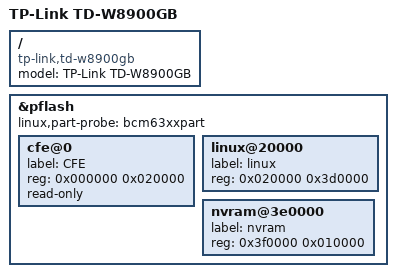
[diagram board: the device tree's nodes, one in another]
/dts-v1/;

/include/ "bcm6348.dtsi"

/ {
	model = "TP-Link TD-W8900GB";
	compatible = "tp-link,td-w8900gb", "brcm,bcm6348";
};

&pflash {
	status = "ok";

	linux,part-probe = "bcm63xxpart";

	cfe@0 {
		label = "CFE";
		reg = <0x000000 0x020000>;
		read-only;
	};

	linux@20000 {
		label = "linux";
		reg = <0x020000 0x3d0000>;
	};

	nvram@3e0000 {
		label = "nvram";
		reg = <0x3f0000 0x010000>;
	};
};
